# PIC32MZ1024EFE124 register map
Vendor: Microchip
Registers are 32-bit, read-write, reset 0x0 unless marked. A register's access mark holds for its fields unless they carry their own. Addresses are absolute, and some are shared; only a register's first bit layout is shown; [hi:lo] are bit positions; {n}, {i} and the like mark numbered series.

## PORTH
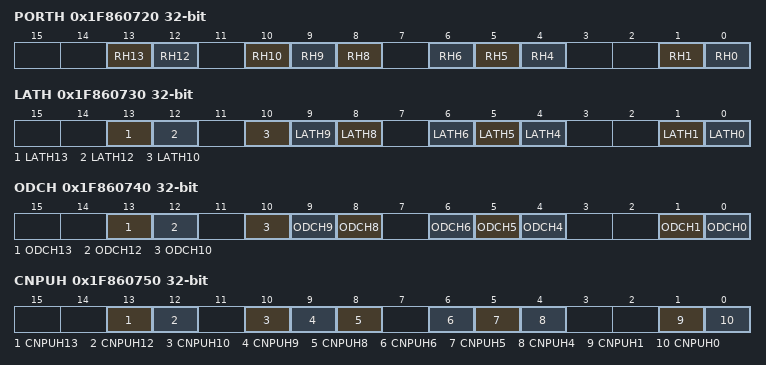
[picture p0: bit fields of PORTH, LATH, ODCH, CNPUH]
0x1F860720 PORTH reset not defined — (power-on value ------------------xx-xxx-xxx--xx)
  [13] RH13, [12] RH12, [10] RH10, [9] RH9, [8] RH8, [6] RH6, [5] RH5, [4] RH4, [1] RH1, [0] RH0
0x1F860730 LATH reset not defined — (power-on value ------------------xx-xxx-xxx--xx)
  [13] LATH13, [12] LATH12, [10] LATH10, [9] LATH9, [8] LATH8, [6] LATH6, [5] LATH5, [4] LATH4, [1] LATH1, [0] LATH0
0x1F860740 ODCH
  [13] ODCH13, [12] ODCH12, [10] ODCH10, [9] ODCH9, [8] ODCH8, [6] ODCH6, [5] ODCH5, [4] ODCH4, [1] ODCH1, [0] ODCH0
0x1F860750 CNPUH
  [13] CNPUH13, [12] CNPUH12, [10] CNPUH10, [9] CNPUH9, [8] CNPUH8, [6] CNPUH6, [5] CNPUH5, [4] CNPUH4, [1] CNPUH1, [0] CNPUH0
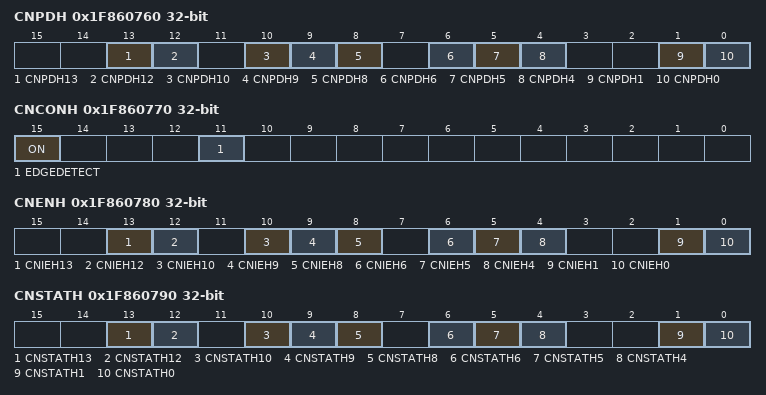
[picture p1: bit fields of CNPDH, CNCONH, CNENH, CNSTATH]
0x1F860760 CNPDH
  [13] CNPDH13, [12] CNPDH12, [10] CNPDH10, [9] CNPDH9, [8] CNPDH8, [6] CNPDH6, [5] CNPDH5, [4] CNPDH4, [1] CNPDH1, [0] CNPDH0
0x1F860770 CNCONH
  [15] ON, [11] EDGEDETECT
0x1F860780 CNENH
  [13] CNIEH13, [12] CNIEH12, [10] CNIEH10, [9] CNIEH9, [8] CNIEH8, [6] CNIEH6, [5] CNIEH5, [4] CNIEH4, [1] CNIEH1, [0] CNIEH0
0x1F860790 CNSTATH
  [13] CNSTATH13, [12] CNSTATH12, [10] CNSTATH10, [9] CNSTATH9, [8] CNSTATH8, [6] CNSTATH6, [5] CNSTATH5, [4] CNSTATH4, [1] CNSTATH1, [0] CNSTATH0
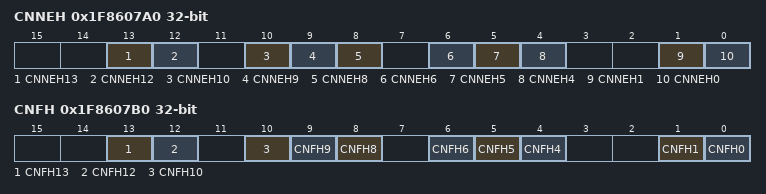
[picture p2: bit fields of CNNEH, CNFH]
0x1F8607A0 CNNEH
  [13] CNNEH13, [12] CNNEH12, [10] CNNEH10, [9] CNNEH9, [8] CNNEH8, [6] CNNEH6, [5] CNNEH5, [4] CNNEH4, [1] CNNEH1, [0] CNNEH0
0x1F8607B0 CNFH
  [13] CNFH13, [12] CNFH12, [10] CNFH10, [9] CNFH9, [8] CNFH8, [6] CNFH6, [5] CNFH5, [4] CNFH4, [1] CNFH1, [0] CNFH0

## PORTJ
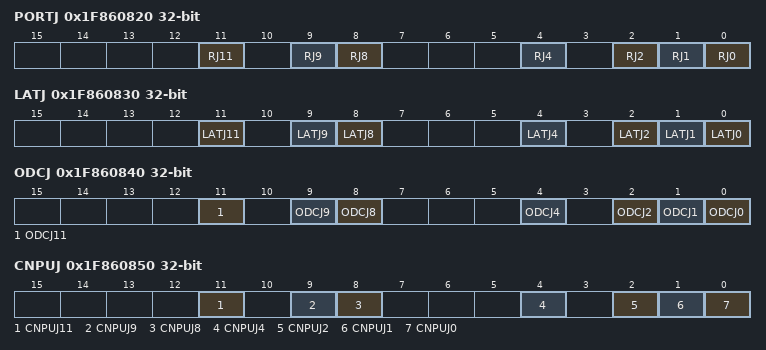
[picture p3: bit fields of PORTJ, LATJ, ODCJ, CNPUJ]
0x1F860820 PORTJ reset not defined — (power-on value --------------------x-xx---x-xxx)
  [11] RJ11, [9] RJ9, [8] RJ8, [4] RJ4, [2] RJ2, [1] RJ1, [0] RJ0
0x1F860830 LATJ reset not defined — (power-on value --------------------x-xx---x-xxx)
  [11] LATJ11, [9] LATJ9, [8] LATJ8, [4] LATJ4, [2] LATJ2, [1] LATJ1, [0] LATJ0
0x1F860840 ODCJ
  [11] ODCJ11, [9] ODCJ9, [8] ODCJ8, [4] ODCJ4, [2] ODCJ2, [1] ODCJ1, [0] ODCJ0
0x1F860850 CNPUJ
  [11] CNPUJ11, [9] CNPUJ9, [8] CNPUJ8, [4] CNPUJ4, [2] CNPUJ2, [1] CNPUJ1, [0] CNPUJ0
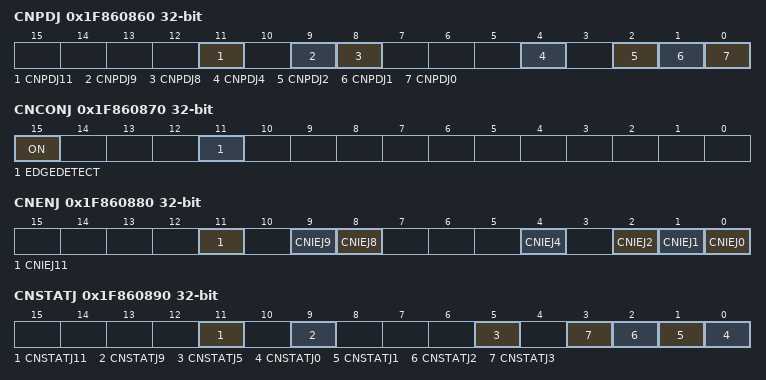
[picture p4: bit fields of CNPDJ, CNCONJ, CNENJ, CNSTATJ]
0x1F860860 CNPDJ
  [11] CNPDJ11, [9] CNPDJ9, [8] CNPDJ8, [4] CNPDJ4, [2] CNPDJ2, [1] CNPDJ1, [0] CNPDJ0
0x1F860870 CNCONJ
  [15] ON, [11] EDGEDETECT
0x1F860880 CNENJ
  [11] CNIEJ11, [9] CNIEJ9, [8] CNIEJ8, [4] CNIEJ4, [2] CNIEJ2, [1] CNIEJ1, [0] CNIEJ0
0x1F860890 CNSTATJ
  [11] CNSTATJ11, [9] CNSTATJ9, [5] CNSTATJ5, [n] CNSTATJ{n} (n=0..3)
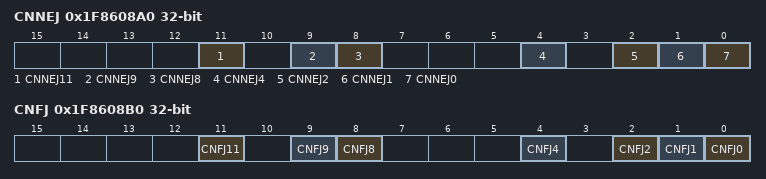
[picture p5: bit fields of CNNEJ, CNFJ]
0x1F8608A0 CNNEJ
  [11] CNNEJ11, [9] CNNEJ9, [8] CNNEJ8, [4] CNNEJ4, [2] CNNEJ2, [1] CNNEJ1, [0] CNNEJ0
0x1F8608B0 CNFJ
  [11] CNFJ11, [9] CNFJ9, [8] CNFJ8, [4] CNFJ4, [2] CNFJ2, [1] CNFJ1, [0] CNFJ0

## usb_clk_rst
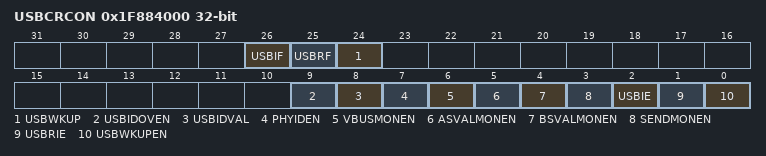
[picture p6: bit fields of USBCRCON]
0x1F884000 USBCRCON
  [26] USBIF ro, [25] USBRF, [24] USBWKUP, [9] USBIDOVEN, [8] USBIDVAL, [7] PHYIDEN, [6] VBUSMONEN, [5] ASVALMONEN, [4] BSVALMONEN, [3] SENDMONEN, [2] USBIE, [1] USBRIE, [0] USBWKUPEN

## PCACHE
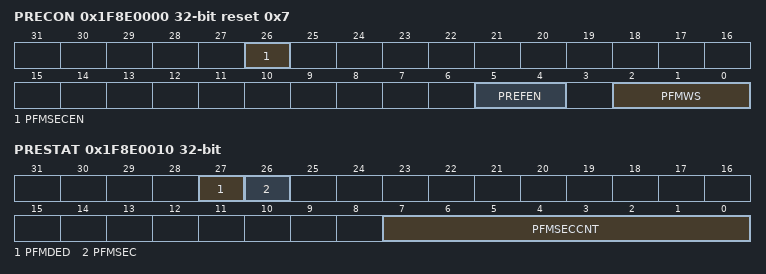
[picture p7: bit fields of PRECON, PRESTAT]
0x1F8E0000 PRECON reset 0x7
  [26] PFMSECEN, [5:4] PREFEN, [2:0] PFMWS
0x1F8E0010 PRESTAT
  [27] PFMDED, [26] PFMSEC, [7:0] PFMSECCNT

## EBI
0x1F8E1014 EBICS0
  [31:16] CSADDR
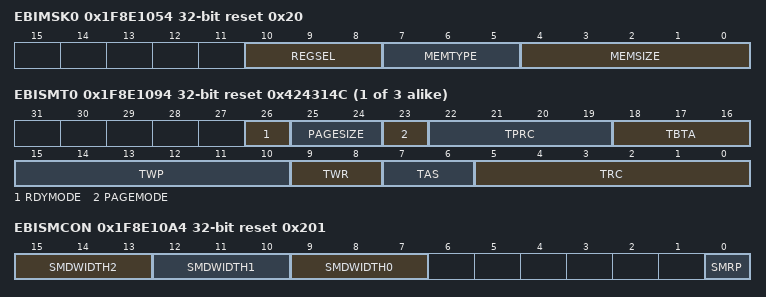
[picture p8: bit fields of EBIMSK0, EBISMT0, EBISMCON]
0x1F8E1054 EBIMSK0 reset 0x20
  [10:8] REGSEL, [7:5] MEMTYPE, [4:0] MEMSIZE
{0x1F8E1094+4i} EBISMT{i} reset 0x424314C (i=0..2)
  [26] RDYMODE, [25:24] PAGESIZE, [23] PAGEMODE, [22:19] TPRC, [18:16] TBTA, [15:10] TWP, [9:8] TWR, [7:6] TAS, [5:0] TRC
0x1F8E10A0 EBIFTRPD reset 0x201
  [31:0] TRPD
0x1F8E10A4 EBISMCON reset 0x201
  [15:13] SMDWIDTH2, [12:10] SMDWIDTH1, [9:7] SMDWIDTH0, [0] SMRP

## DOS_EIP_00124_usb_hs_otgcore
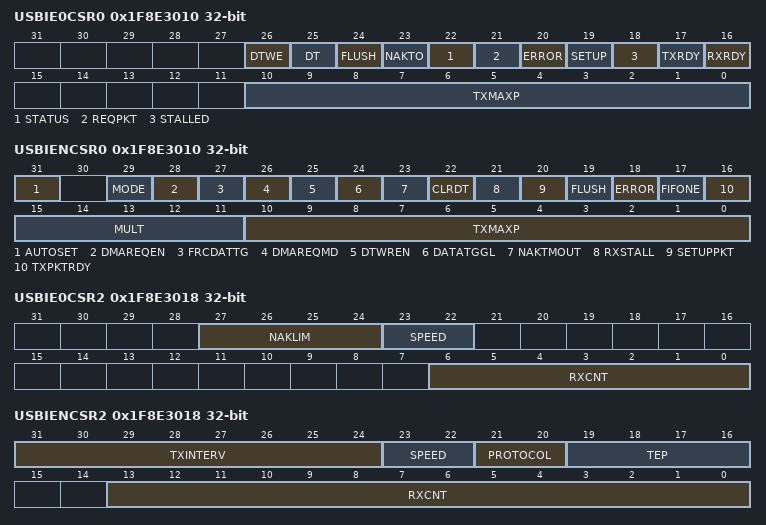
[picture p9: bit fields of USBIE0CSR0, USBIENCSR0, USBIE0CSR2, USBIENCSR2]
0x1F8E3010 USBIE0CSR0
  [26] DTWE, [25] DT, [24] FLUSH, [23] NAKTO, [22] STATUS, [21] REQPKT, [20] ERROR, [19] SETUP, [18] STALLED, [17] TXRDY, [16] RXRDY, [10:0] TXMAXP
0x1F8E3010 USBIENCSR0
  [31] AUTOSET, [29] MODE, [28] DMAREQEN, [27] FRCDATTG, [26] DMAREQMD, [25] DTWREN, [24] DATATGGL, [23] NAKTMOUT, [22] CLRDT, [21] RXSTALL, [20] SETUPPKT, [19] FLUSH, [18] ERROR, [17] FIFONE, [16] TXPKTRDY, [15:11] MULT, [10:0] TXMAXP
0x1F8E3018 USBIE0CSR2
  [27:24] NAKLIM, [23:22] SPEED, [6:0] RXCNT ro
0x1F8E3018 USBIENCSR2
  [31:24] TXINTERV, [23:22] SPEED, [21:20] PROTOCOL, [19:16] TEP, [13:0] RXCNT ro
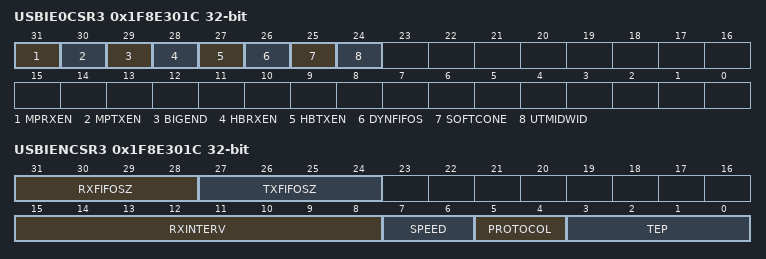
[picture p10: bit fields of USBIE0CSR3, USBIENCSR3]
0x1F8E301C USBIE0CSR3 ro reset not defined — (power-on value xx0xxx10------------------------)
  [31] MPRXEN, [30] MPTXEN, [29] BIGEND, [28] HBRXEN, [27] HBTXEN, [26] DYNFIFOS, [25] SOFTCONE, [24] UTMIDWID
0x1F8E301C USBIENCSR3 reset not defined — (power-on value xxxxxxxx--------0000000000000000)
  [31:28] RXFIFOSZ ro, [27:24] TXFIFOSZ ro, [15:8] RXINTERV, [7:6] SPEED, [5:4] PROTOCOL, [3:0] TEP
